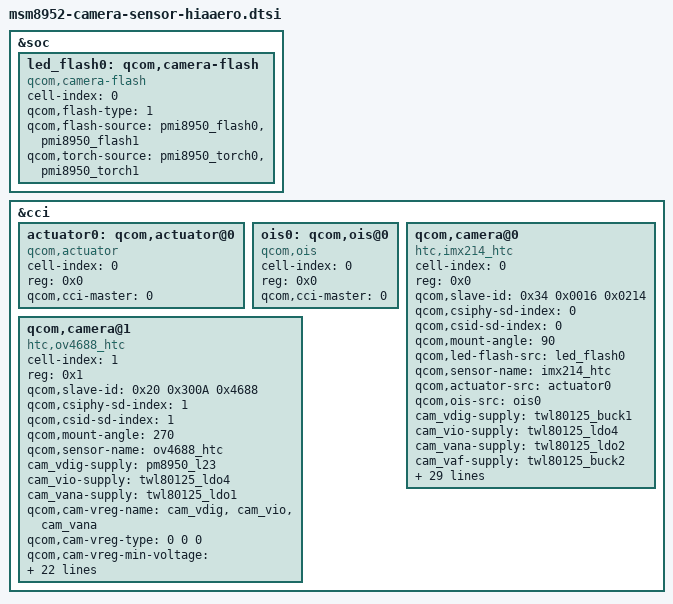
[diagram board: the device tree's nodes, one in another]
/*
 * Copyright (c) 2015, The Linux Foundation. All rights reserved.
 *
 * This program is free software; you can redistribute it and/or modify
 * it under the terms of the GNU General Public License version 2 and
 * only version 2 as published by the Free Software Foundation.
 *
 * This program is distributed in the hope that it will be useful,
 * but WITHOUT ANY WARRANTY; without even the implied warranty of
 * MERCHANTABILITY or FITNESS FOR A PARTICULAR PURPOSE.  See the
 * GNU General Public License for more details.
 */

&soc {
	led_flash0: qcom,camera-flash {
		cell-index = <0>;
		compatible = "qcom,camera-flash";
		qcom,flash-type = <1>;
		qcom,flash-source = <&pmi8950_flash0 &pmi8950_flash1>;
		qcom,torch-source = <&pmi8950_torch0 &pmi8950_torch1>;
	};
};
&cci {
	actuator0: qcom,actuator@0 {
		cell-index = <0>;
		reg = <0x0>;
		compatible = "qcom,actuator";
		qcom,cci-master = <0>;
	};

	ois0: qcom,ois@0 {
		cell-index = <0>;
		reg = <0x0>;
		compatible = "qcom,ois";
		qcom,cci-master = <0>;
	};

	qcom,camera@0 {
		cell-index = <0>;
		compatible = "htc,imx214_htc";
		reg = <0x0>;
		qcom,slave-id = <0x34 0x0016 0x0214>;
		qcom,csiphy-sd-index = <0>;
		qcom,csid-sd-index = <0>;
		qcom,mount-angle = <90>;
                qcom,led-flash-src = <&led_flash0>;
		qcom,sensor-name = "imx214_htc";
		qcom,actuator-src = <&actuator0>;
		qcom,ois-src = <&ois0>;
		cam_vdig-supply = <&twl80125_buck1>;
		cam_vio-supply = <&twl80125_ldo4>;
		cam_vana-supply = <&twl80125_ldo2>;
		cam_vaf-supply = <&twl80125_buck2>;
		cam_vcustom1-supply = <&twl80125_ldo3>;
		qcom,cam-vreg-name = "cam_vdig", "cam_vio", "cam_vana", "cam_vaf","cam_vcustom1";
		qcom,cam-vreg-type = <0 0 0 0 0>;
		qcom,cam-vreg-min-voltage = <1000000 1800000 2800000 2850000 2800000>;
		qcom,cam-vreg-max-voltage = <1000000 1800000 2800000 2850000 2800000>;
		qcom,cam-vreg-op-mode = <0 0 0 0 0>;
		qcom,cam-vreg-gpios-index = <99 99 99 99 99>;
		qcom,gpio-no-mux = <0>;
		pinctrl-names = "cam_default", "cam_suspend";
		pinctrl-0 = <&cam_sensor_mclk0_default
				&cam_sensor_rear_default
				&cam_sensor_ext_gpio_default>;
		pinctrl-1 = <&cam_sensor_mclk0_sleep
				&cam_sensor_rear_sleep
				&cam_sensor_ext_gpio_sleep>;
		gpios = <&msm_gpio 26 0>,
			<&msm_gpio 36 0>;
		qcom,gpio-reset = <1>;
		qcom,gpio-req-tbl-num = <0 1>;
		qcom,gpio-req-tbl-flags = <1 0>;
		qcom,gpio-req-tbl-label = "CAMIF_MCLK",
					  "CAM_RST";
		qcom,csi-lane-assign = <0x4320>;
		qcom,csi-lane-mask = <0x1F>;
		qcom,sensor-position = <0>;
		qcom,sensor-mode = <0>;
		qcom,cci-master = <0>;
		status = "ok";
		clocks = <&clock_gcc clk_mclk0_clk_src>,
				<&clock_gcc clk_gcc_camss_mclk0_clk>;
		clock-names = "cam_src_clk", "cam_clk";
	};
	qcom,camera@1 {
		cell-index = <1>;
		compatible = "htc,ov4688_htc";
		reg = <0x1>;
		qcom,slave-id = <0x20 0x300A 0x4688>;
		qcom,csiphy-sd-index = <1>;
		qcom,csid-sd-index = <1>;
		qcom,mount-angle = <270>;
		qcom,sensor-name = "ov4688_htc";
		cam_vdig-supply = <&pm8950_l23>;
		cam_vio-supply = <&twl80125_ldo4>;
		cam_vana-supply = <&twl80125_ldo1>;
		qcom,cam-vreg-name = "cam_vdig", "cam_vio", "cam_vana";
		qcom,cam-vreg-type = <0 0 0>;
		qcom,cam-vreg-min-voltage = <1200000 1800000 2800000>;
		qcom,cam-vreg-max-voltage = <1200000 1800000 2800000>;
		qcom,cam-vreg-op-mode = <0 0 0>;
		qcom,cam-vreg-gpios-index = <99 99 99>;
		qcom,gpio-no-mux = <0>;
		pinctrl-names = "cam_default", "cam_suspend";
		pinctrl-0 = <&cam_sensor_mclk2_default &cam_sensor_front_default>;
		pinctrl-1 = <&cam_sensor_mclk2_sleep &cam_sensor_front_sleep>;
		gpios = <&msm_gpio 28 0>,
			<&msm_gpio 38 0>;
		qcom,gpio-reset = <1>;
		qcom,gpio-req-tbl-num = <0 1>;
		qcom,gpio-req-tbl-flags = <1 0>;
		qcom,gpio-req-tbl-label = "CAMIF_MCLK",
					"CAM_RST";
		qcom,csi-lane-assign = <0x4320>;
		qcom,csi-lane-mask = <0x1F>;
		qcom,sensor-position = <1>;
		qcom,sensor-mode = <1>;
		qcom,cci-master = <0>;
		status = "ok";
		clocks = <&clock_gcc clk_mclk2_clk_src>,
				<&clock_gcc clk_gcc_camss_mclk2_clk>;
		clock-names = "cam_src_clk", "cam_clk";
	};
};
